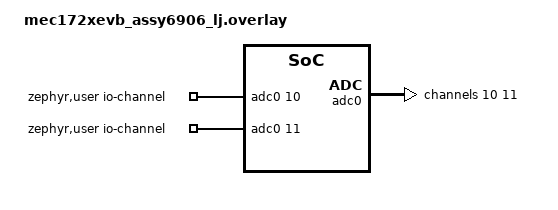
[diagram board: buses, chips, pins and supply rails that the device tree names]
/*
 * SPDX-License-Identifier: Apache-2.0
 *
 * Copyright (c) Benjamin Björnsson <benjamin.bjornsson@gmail.com>
 */

/ {
	zephyr,user {
		io-channels = <&adc0 10>, <&adc0 11>;
	};
};

&adc0 {
	#address-cells = <1>;
	#size-cells = <0>;

	channel@10 {
		reg = <10>;
		zephyr,gain = "ADC_GAIN_1";
		zephyr,reference = "ADC_REF_INTERNAL";
		zephyr,acquisition-time = <ADC_ACQ_TIME_DEFAULT>;
		zephyr,resolution = <12>;
	};

	channel@11 {
		reg = <11>;
		zephyr,gain = "ADC_GAIN_1";
		zephyr,reference = "ADC_REF_INTERNAL";
		zephyr,acquisition-time = <ADC_ACQ_TIME_DEFAULT>;
		zephyr,resolution = <12>;
	};
};
